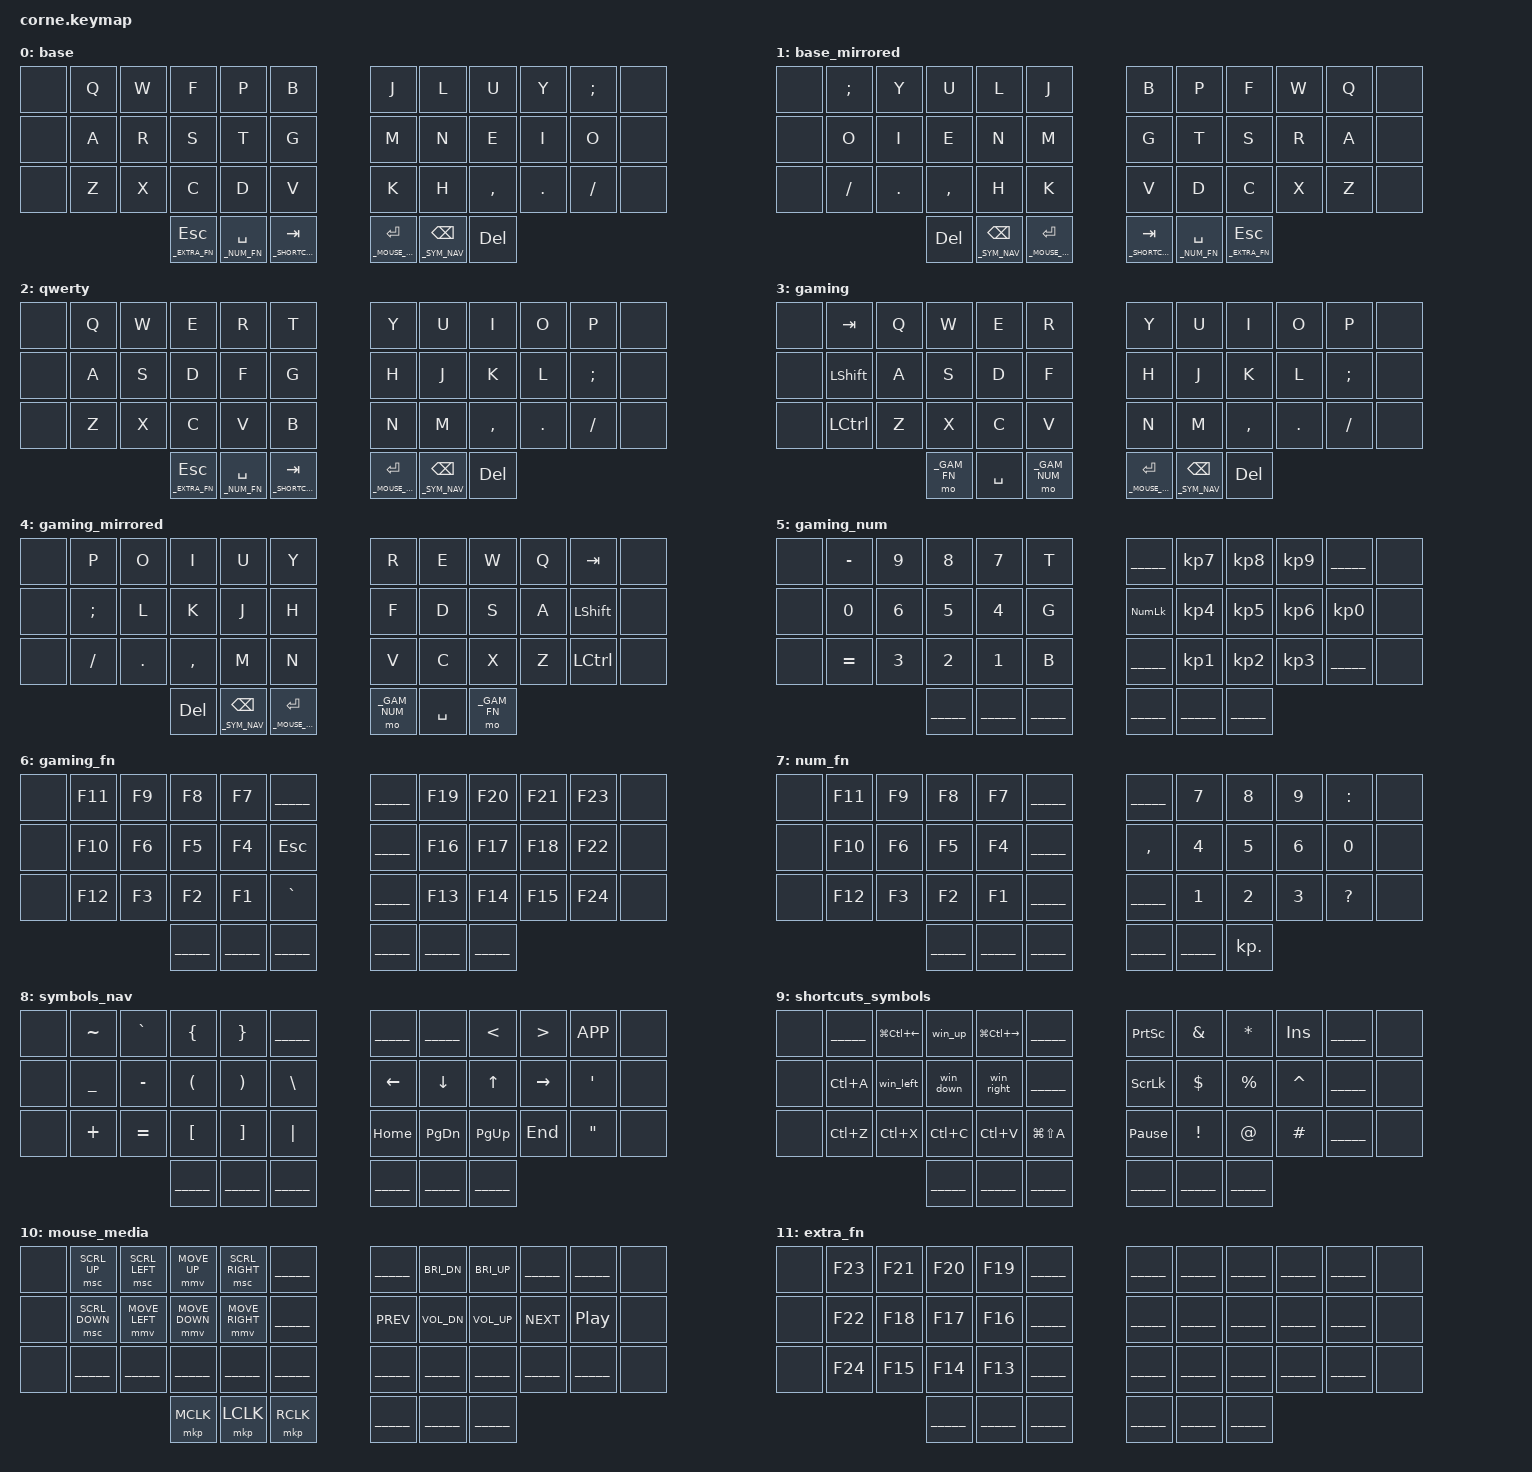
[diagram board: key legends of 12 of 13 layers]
/*
 * Copyright (c) 2020 The ZMK Contributors
 *
 * SPDX-License-Identifier: MIT
 */

#include <behaviors.dtsi>
#include <dt-bindings/zmk/keys.h>
#include <dt-bindings/zmk/bt.h>
#include <dt-bindings/zmk/outputs.h>

#define ZMK_POINTING_DEFAULT_MOVE_VAL 1500
#define ZMK_POINTING_DEFAULT_SCRL_VAL 100 // https://zmk.dev/docs/keymaps/behaviors/mouse-emulation#examples-2
#include <dt-bindings/zmk/pointing.h>

#define _____ trans

#define _BASE 0
#define _BASE_MIR 1
#define _QWERTY 2
#define _GAMING 3
#define _GAM_MIR 4
#define _GAM_NUM 5
#define _GAM_FN 6
#define _NUM_FN 7
#define _SYM_NAV 8
#define _SHORTCUTS_SYM 9
#define _MOUSE_MEDIA 10
#define _EXTRA_FN 11
#define _CONFIG 12

#define COMBO_STICKY_MOD(MOD, KEY_POSITIONS) \
    combo_sticky_mod_##MOD { \
        bindings = <&sk MOD>; \
        timeout-ms = <200>; \
        key-positions = <KEY_POSITIONS>; \
        layers = <_BASE _BASE_MIR _QWERTY>; \
    };

#define COMBO_MOD(MOD, KEY_POSITIONS) \
    combo_mod_##MOD { \
        bindings = <&kp MOD>; \
        timeout-ms = <200>; \
        key-positions = <KEY_POSITIONS>; \
        layers = <_BASE _BASE_MIR _QWERTY _NUM_FN _SYM_NAV _SHORTCUTS_SYM>; \
    };

#define COMBO_STANDARD(NAME, BINDINGS, KEY_POSITIONS, LAYERS) \
    combo_standard_##NAME { \
        bindings = <BINDINGS>; \
        timeout-ms = <200>; \
        key-positions = <KEY_POSITIONS>; \
        layers = <LAYERS>; \
    };

&sk {
    release-after-ms = <2000>;
    quick-release;
};

&sl {
    release-after-ms = <2000>;
};

&lt {
    flavor = "hold-preferred";
    quick-tap-ms = <200>;
};

&caps_word {
    continue-list = <UNDER MINUS BSPC DEL>;
};

&mmv {
    time-to-max-speed-ms = <1000>;
};

&msc {
    acceleration-exponent = <1>;
    time-to-max-speed-ms = <1000>;
};

/ {
    combos {
        compatible = "zmk,combos";

        COMBO_STICKY_MOD(LGUI, 1 13)
        COMBO_STICKY_MOD(LALT, 2 14)
        COMBO_STICKY_MOD(LCTRL, 3 15)
        COMBO_STICKY_MOD(LSHFT, 4 16)

        COMBO_STICKY_MOD(RSHFT, 7 19)
        COMBO_STICKY_MOD(RCTRL, 8 20)
        COMBO_STICKY_MOD(RALT, 9 21)
        COMBO_STICKY_MOD(RGUI, 10 22)

        COMBO_MOD(LGUI, 13 25)
        COMBO_MOD(LALT, 14 26)
        COMBO_MOD(LCTRL, 15 27)
        COMBO_MOD(LSHFT, 16 28)

        COMBO_MOD(RSHFT, 19 31)
        COMBO_MOD(RCTRL, 20 32)
        COMBO_MOD(RALT, 21 33)
        COMBO_MOD(RGUI, 22 34)

        COMBO_STANDARD(lock, &kp LG(L), 4 5, _BASE _QWERTY)
        COMBO_STANDARD(search_key, &kp C_AC_SEARCH, 16 17, _BASE _QWERTY)
        COMBO_STANDARD(base_to_gaming, &to _GAMING, 28 29, _BASE)

        COMBO_STANDARD(base_mirrored_l, &sl _BASE_MIR, 37 38, _BASE)
        COMBO_STANDARD(base_mirrored_r, &sl _BASE_MIR, 39 40, _BASE)

        COMBO_STANDARD(gaming_to_base, &to _BASE, 18 19, _GAMING)
        COMBO_STANDARD(gaming_alt, &kp LALT, 36 37, _GAMING)
        COMBO_STANDARD(gaming_mirrored, &sl _GAM_MIR, 37 38, _GAMING)

        COMBO_STANDARD(win_shift_left, &kp LG(LS(LEFT)), 14 15, _SHORTCUTS_SYM)
        COMBO_STANDARD(win_shift_right, &kp LG(LS(RIGHT)), 15 16, _SHORTCUTS_SYM)

        combo_config {
            key-positions = <36 41>;  // inner L1+R1
            bindings = <&mo _CONFIG>;
            timeout-ms = <100>;
        };

        combo_caps_word {
            key-positions = <37 40>;  // home L1+R1
            bindings = <&caps_word>;
        };

    };

    macros {
        // HACK fix buggy LGUI(key) shortcuts
        ZMK_MACRO(win_up,
            wait-ms = <40>;
            tap-ms = <40>;
            bindings =
                <&macro_press &kp LGUI>,
                <&macro_tap &kp UP>,
                <&macro_release &kp LGUI>
                ;
        )
        ZMK_MACRO(win_down,
            wait-ms = <40>;
            tap-ms = <40>;
            bindings =
                <&macro_press &kp LGUI>,
                <&macro_tap &kp DOWN>,
                <&macro_release &kp LGUI>
                ;
        )
        ZMK_MACRO(win_left,
            wait-ms = <40>;
            tap-ms = <40>;
            bindings =
                <&macro_press &kp LGUI>,
                <&macro_tap &kp LEFT>,
                <&macro_release &kp LGUI>
                ;
        )
        ZMK_MACRO(win_right,
            wait-ms = <40>;
            tap-ms = <40>;
            bindings =
                <&macro_press &kp LGUI>,
                <&macro_tap &kp RIGHT>,
                <&macro_release &kp LGUI>
                ;
        )

    };

    keymap {
        compatible = "zmk,keymap";

        base {
            bindings = <
                &none &kp Q &kp W &kp F &kp P &kp B /**/ &kp J &kp L &kp U     &kp Y   &kp SEMI &none
                &none &kp A &kp R &kp S &kp T &kp G /**/ &kp M &kp N &kp E     &kp I   &kp O    &none
                &none &kp Z &kp X &kp C &kp D &kp V /**/ &kp K &kp H &kp COMMA &kp DOT &kp FSLH &none
                /* thumb keys */
                &lt _EXTRA_FN ESC &lt _NUM_FN SPACE &lt _SHORTCUTS_SYM TAB /**/ &lt _MOUSE_MEDIA ENTER &lt _SYM_NAV BSPC &kp DEL
            >;
        };

        base_mirrored {
            bindings = <
                &none &kp SEMI &kp Y   &kp U     &kp L &kp J /**/ &kp B &kp P &kp F &kp W &kp Q &none
                &none &kp O    &kp I   &kp E     &kp N &kp M /**/ &kp G &kp T &kp S &kp R &kp A &none
                &none &kp FSLH &kp DOT &kp COMMA &kp H &kp K /**/ &kp V &kp D &kp C &kp X &kp Z &none
                /* thumb keys */
                &kp DEL &lt _SYM_NAV BSPC &lt _MOUSE_MEDIA ENTER /**/ &lt _SHORTCUTS_SYM TAB &lt _NUM_FN SPACE &lt _EXTRA_FN ESC
            >;
        };

        qwerty {
            bindings = <
                &none &kp Q &kp W &kp E &kp R &kp T /**/ &kp Y &kp U &kp I     &kp O   &kp P    &none
                &none &kp A &kp S &kp D &kp F &kp G /**/ &kp H &kp J &kp K     &kp L   &kp SEMI &none
                &none &kp Z &kp X &kp C &kp V &kp B /**/ &kp N &kp M &kp COMMA &kp DOT &kp FSLH &none
                /* thumb keys */
                &lt _EXTRA_FN ESC &lt _NUM_FN SPACE &lt _SHORTCUTS_SYM TAB /**/ &lt _MOUSE_MEDIA ENTER &lt _SYM_NAV BSPC &kp DEL
            >;
        };

        gaming {
            bindings = <
                &none &kp TAB   &kp Q &kp W &kp E &kp R /**/ &kp Y &kp U &kp I     &kp O   &kp P    &none
                &none &kp LSHFT &kp A &kp S &kp D &kp F /**/ &kp H &kp J &kp K     &kp L   &kp SEMI &none
                &none &kp LCTRL &kp Z &kp X &kp C &kp V /**/ &kp N &kp M &kp COMMA &kp DOT &kp FSLH &none
                /* thumb keys */
                &mo _GAM_FN &kp SPACE &mo _GAM_NUM /**/ &lt _MOUSE_MEDIA ENTER &lt _SYM_NAV BSPC &kp DEL
            >;
        };

        gaming_mirrored {
            bindings = <
                &none &kp P    &kp O   &kp I     &kp U &kp Y /**/ &kp R &kp E &kp W &kp Q &kp TAB   &none
                &none &kp SEMI &kp L   &kp K     &kp J &kp H /**/ &kp F &kp D &kp S &kp A &kp LSHFT &none
                &none &kp FSLH &kp DOT &kp COMMA &kp M &kp N /**/ &kp V &kp C &kp X &kp Z &kp LCTRL &none
                /* thumb keys */
                &kp DEL &lt _SYM_NAV BSPC &lt _MOUSE_MEDIA ENTER /**/ &mo _GAM_NUM &kp SPACE &mo _GAM_FN
            >;
        };

        gaming_num {
            bindings = <
                &none &kp MINUS &kp N9 &kp N8 &kp N7 &kp T /**/ &_____     &kp KP_N7 &kp KP_N8 &kp KP_N9 &_____    &none
                &none &kp N0    &kp N6 &kp N5 &kp N4 &kp G /**/ &kp KP_NUM &kp KP_N4 &kp KP_N5 &kp KP_N6 &kp KP_N0 &none
                &none &kp EQUAL &kp N3 &kp N2 &kp N1 &kp B /**/ &_____     &kp KP_N1 &kp KP_N2 &kp KP_N3 &_____    &none
                /* thumb keys */
                &_____ &_____ &_____ /**/ &_____ &_____ &_____
            >;
        };

        gaming_fn {
            bindings = <
                &none &kp F11 &kp F9 &kp F8 &kp F7 &_____    /**/ &_____ &kp F19 &kp F20 &kp F21 &kp F23 &none
                &none &kp F10 &kp F6 &kp F5 &kp F4 &kp ESC   /**/ &_____ &kp F16 &kp F17 &kp F18 &kp F22 &none
                &none &kp F12 &kp F3 &kp F2 &kp F1 &kp GRAVE /**/ &_____ &kp F13 &kp F14 &kp F15 &kp F24 &none
                /* thumb keys */
                &_____ &_____ &_____ /**/ &_____ &_____ &_____
            >;
        };

        num_fn {
            bindings = <
                &none &kp F11 &kp F9 &kp F8 &kp F7 &_____ /**/ &_____    &kp N7 &kp N8 &kp N9 &kp COLON &none
                &none &kp F10 &kp F6 &kp F5 &kp F4 &_____ /**/ &kp COMMA &kp N4 &kp N5 &kp N6 &kp N0    &none
                &none &kp F12 &kp F3 &kp F2 &kp F1 &_____ /**/ &_____    &kp N1 &kp N2 &kp N3 &kp QMARK &none
                /* thumb keys */
                &_____ &_____ &_____ /**/ &_____ &_____ &kp KP_DOT
            >;
        };

        symbols_nav {
            bindings = <
                &none &kp TILDE &kp GRAVE &kp LBRC &kp RBRC &_____   /**/ &_____   &_____    &kp LT    &kp GT    &kp K_APP &none
                &none &kp UNDER &kp MINUS &kp LPAR &kp RPAR &kp BSLH /**/ &kp LEFT &kp DOWN  &kp UP    &kp RIGHT &kp SQT   &none
                &none &kp PLUS  &kp EQUAL &kp LBKT &kp RBKT &kp PIPE /**/ &kp HOME &kp PG_DN &kp PG_UP &kp END   &kp DQT   &none
                /* thumb keys */
                &_____ &_____ &_____ /**/ &_____ &_____ &_____
            >;
        };

        shortcuts_symbols {
            bindings = <
                &none &_____    &kp LG(LC(LEFT)) &win_up   &kp LG(LC(RIGHT)) &_____        /**/ &kp PSCRN       &kp AMPS &kp STAR  &kp INS   &_____ &none
                &none &kp LC(A) &win_left        &win_down &win_right        &_____        /**/ &kp SLCK        &kp DLLR &kp PRCNT &kp CARET &_____ &none
                &none &kp LC(Z) &kp LC(X)        &kp LC(C) &kp LC(V)         &kp LG(LS(A)) /**/ &kp PAUSE_BREAK &kp EXCL &kp AT    &kp HASH  &_____ &none
                /* thumb keys */
                &_____ &_____ &_____ /**/ &_____ &_____ &_____
            >;
        };

        mouse_media {
            bindings = <
                &none &msc SCRL_UP   &msc SCRL_LEFT &mmv MOVE_UP   &msc SCRL_RIGHT &_____ /**/ &_____     &kp C_BRI_DN &kp C_BRI_UP &_____     &_____   &none
                &none &msc SCRL_DOWN &mmv MOVE_LEFT &mmv MOVE_DOWN &mmv MOVE_RIGHT &_____ /**/ &kp C_PREV &kp C_VOL_DN &kp C_VOL_UP &kp C_NEXT &kp C_PP &none
                &none &_____         &_____         &_____         &_____          &_____ /**/ &_____     &_____       &_____       &_____     &_____   &none
                /* thumb keys */
                &mkp MCLK &mkp LCLK &mkp RCLK /**/ &_____ &_____ &_____
            >;
        };

        extra_fn {
            bindings = <
                &none &kp F23 &kp F21 &kp F20 &kp F19 &_____ /**/ &_____ &_____ &_____ &_____ &_____ &none
                &none &kp F22 &kp F18 &kp F17 &kp F16 &_____ /**/ &_____ &_____ &_____ &_____ &_____ &none
                &none &kp F24 &kp F15 &kp F14 &kp F13 &_____ /**/ &_____ &_____ &_____ &_____ &_____ &none
                /* thumb keys */
                &_____ &_____ &_____ /**/ &_____ &_____ &_____
            >;
        };

        config {
            bindings = <
                &none &_____       &_____ &_____      &_____    &_____ /**/ &_____     &_____       &_____       &_____       &_____       &none
                &none &_____       &_____ &_____      &_____    &_____ /**/ &_____     &bt BT_SEL 3 &_____       &_____       &_____       &none
                &none &out OUT_USB &_____ &to _QWERTY &to _BASE &_____ /**/ &bt BT_CLR &bt BT_SEL 0 &bt BT_SEL 1 &bt BT_SEL 2 &out OUT_BLE &none
                /* thumb keys */
                &_____ &sys_reset &bootloader /**/ &bootloader &sys_reset &_____
            >;
        };

    };
};
